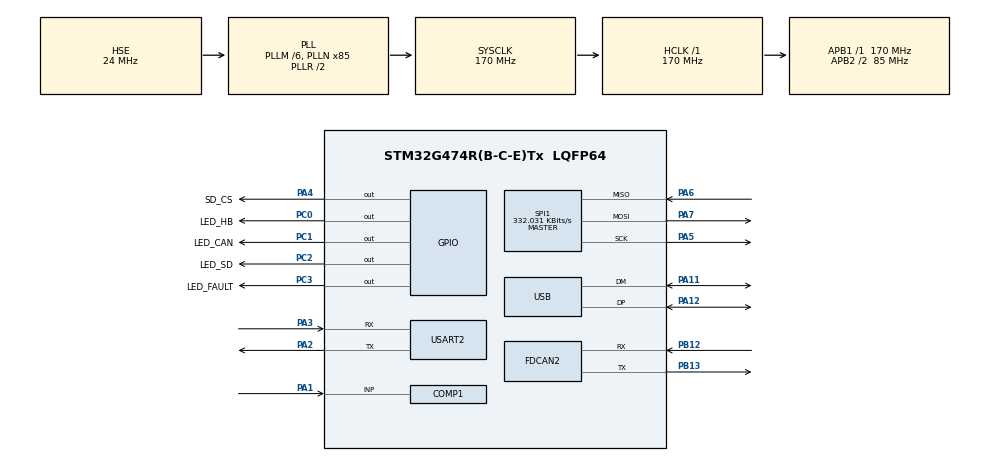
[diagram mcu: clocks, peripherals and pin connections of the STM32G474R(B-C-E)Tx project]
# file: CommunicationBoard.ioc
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COMP1.Hysteresis=COMP_HYSTERESIS_20MV
COMP1.TriggerMode=COMP_TRIGGERMODE_IT_FALLING
Dma.Request0=SPI1_RX
Dma.Request1=SPI1_TX
Dma.Request2=USART2_TX
Dma.SPI1_RX.0.Direction=DMA_PERIPH_TO_MEMORY
Dma.SPI1_RX.0.EventEnable=DISABLE
Dma.SPI1_RX.0.Instance=DMA1_Channel1
Dma.SPI1_RX.0.MemDataAlignment=DMA_MDATAALIGN_BYTE
Dma.SPI1_RX.0.MemInc=DMA_MINC_ENABLE
Dma.SPI1_RX.0.Mode=DMA_NORMAL
Dma.SPI1_RX.0.PeriphDataAlignment=DMA_PDATAALIGN_BYTE
Dma.SPI1_RX.0.PeriphInc=DMA_PINC_DISABLE
Dma.SPI1_RX.0.Polarity=HAL_DMAMUX_REQ_GEN_RISING
Dma.SPI1_RX.0.Priority=DMA_PRIORITY_LOW
Dma.SPI1_RX.0.RequestNumber=1
Dma.SPI1_RX.0.SignalID=NONE
Dma.SPI1_RX.0.SyncEnable=DISABLE
Dma.SPI1_RX.0.SyncPolarity=HAL_DMAMUX_SYNC_NO_EVENT
Dma.SPI1_RX.0.SyncRequestNumber=1
Dma.SPI1_RX.0.SyncSignalID=NONE
Dma.SPI1_TX.1.Direction=DMA_MEMORY_TO_PERIPH
Dma.SPI1_TX.1.EventEnable=DISABLE
Dma.SPI1_TX.1.Instance=DMA1_Channel2
Dma.SPI1_TX.1.MemDataAlignment=DMA_MDATAALIGN_BYTE
Dma.SPI1_TX.1.MemInc=DMA_MINC_ENABLE
Dma.SPI1_TX.1.Mode=DMA_NORMAL
Dma.SPI1_TX.1.PeriphDataAlignment=DMA_PDATAALIGN_BYTE
Dma.SPI1_TX.1.PeriphInc=DMA_PINC_DISABLE
Dma.SPI1_TX.1.Polarity=HAL_DMAMUX_REQ_GEN_RISING
Dma.SPI1_TX.1.Priority=DMA_PRIORITY_LOW
Dma.SPI1_TX.1.RequestNumber=1
Dma.SPI1_TX.1.SignalID=NONE
Dma.SPI1_TX.1.SyncEnable=DISABLE
Dma.SPI1_TX.1.SyncPolarity=HAL_DMAMUX_SYNC_NO_EVENT
Dma.SPI1_TX.1.SyncRequestNumber=1
Dma.SPI1_TX.1.SyncSignalID=NONE
Dma.USART2_TX.2.Direction=DMA_MEMORY_TO_PERIPH
Dma.USART2_TX.2.EventEnable=DISABLE
Dma.USART2_TX.2.Instance=DMA1_Channel3
Dma.USART2_TX.2.MemDataAlignment=DMA_MDATAALIGN_BYTE
Dma.USART2_TX.2.MemInc=DMA_MINC_ENABLE
Dma.USART2_TX.2.Mode=DMA_NORMAL
Dma.USART2_TX.2.PeriphDataAlignment=DMA_PDATAALIGN_BYTE
Dma.USART2_TX.2.PeriphInc=DMA_PINC_DISABLE
Dma.USART2_TX.2.Polarity=HAL_DMAMUX_REQ_GEN_RISING
Dma.USART2_TX.2.Priority=DMA_PRIORITY_LOW
Dma.USART2_TX.2.RequestNumber=1
Dma.USART2_TX.2.SignalID=NONE
Dma.USART2_TX.2.SyncEnable=DISABLE
Dma.USART2_TX.2.SyncPolarity=HAL_DMAMUX_SYNC_NO_EVENT
Dma.USART2_TX.2.SyncRequestNumber=1
Dma.USART2_TX.2.SyncSignalID=NONE
FATFS._FS_REENTRANT=0
FATFS._USE_EXPAND=1
FATFS._USE_LFN=1
FDCAN2.AutoRetransmission=ENABLE
FDCAN2.CalculateBaudRateNominal=999999
FDCAN2.CalculateTimeBitNominal=1000
FDCAN2.CalculateTimeQuantumNominal=58.82352941176471
FDCAN2.NominalPrescaler=10
FDCAN2.NominalSyncJumpWidth=2
FDCAN2.NominalTimeSeg1=14
FDCAN2.NominalTimeSeg2=2
FDCAN2.StdFiltersNbr=1
IWDG.Prescaler=IWDG_PRESCALER_32
IWDG.Reload=1999
Mcu.Family=STM32G4
Mcu.Name=STM32G474R(B-C-E)Tx
Mcu.Package=LQFP64
NVIC.COMP1_2_3_IRQn=true\:5\:0\:false\:false\:true\:false\:true\:true
NVIC.DMA1_Channel1_IRQn=true\:7\:0\:false\:false\:true\:false\:true\:true
NVIC.DMA1_Channel2_IRQn=true\:7\:0\:false\:false\:true\:false\:true\:true
NVIC.DMA1_Channel3_IRQn=true\:10\:0\:false\:false\:true\:false\:true\:true
NVIC.FDCAN2_IT0_IRQn=true\:6\:0\:false\:false\:true\:false\:true\:true
NVIC.PriorityGroup=NVIC_PRIORITYGROUP_4
NVIC.TIM2_IRQn=true\:9\:0\:false\:false\:true\:false\:true\:true
NVIC.USART2_IRQn=true\:10\:0\:false\:false\:true\:false\:true\:true
PA1.Mode=INP
PA1.Signal=COMP1_INP
PA11.Mode=Device
PA11.Signal=USB_DM
PA12.Mode=Device
PA12.Signal=USB_DP
PA13.Mode=Serial_Wire
PA13.Signal=SYS_JTMS-SWDIO
PA14.Mode=Serial_Wire
PA14.Signal=SYS_JTCK-SWCLK
PA2.Mode=Asynchronous
PA2.Signal=USART2_TX
PA3.Mode=Asynchronous
PA3.Signal=USART2_RX
PA4.GPIO_Label=SD_CS
PA4.PinState=GPIO_PIN_SET
PA4.Signal=GPIO_Output
PA5.GPIO_Speed=GPIO_SPEED_FREQ_VERY_HIGH
PA5.Mode=Full_Duplex_Master
PA5.Signal=SPI1_SCK
PA6.GPIO_PuPd=GPIO_PULLUP
PA6.GPIO_Speed=GPIO_SPEED_FREQ_VERY_HIGH
PA6.Mode=Full_Duplex_Master
PA6.Signal=SPI1_MISO
PA7.GPIO_Speed=GPIO_SPEED_FREQ_VERY_HIGH
PA7.Mode=Full_Duplex_Master
PA7.Signal=SPI1_MOSI
PB12.Mode=FDCAN_Activate
PB12.Signal=FDCAN2_RX
PB13.Mode=FDCAN_Activate
PB13.Signal=FDCAN2_TX
PC0.GPIO_Label=LED_HB
PC0.Signal=GPIO_Output
PC1.GPIO_Label=LED_CAN
PC1.Signal=GPIO_Output
PC14-OSC32_IN.Mode=LSE-External-Oscillator
PC14-OSC32_IN.Signal=RCC_OSC32_IN
PC15-OSC32_OUT.Mode=LSE-External-Oscillator
PC15-OSC32_OUT.Signal=RCC_OSC32_OUT
PC2.GPIO_Label=LED_SD
PC2.Signal=GPIO_Output
PC3.GPIO_Label=LED_FAULT
PC3.Signal=GPIO_Output
PF0-OSC_IN.Mode=HSE-External-Oscillator
PF0-OSC_IN.Signal=RCC_OSC_IN
PF1-OSC_OUT.Mode=HSE-External-Oscillator
PF1-OSC_OUT.Signal=RCC_OSC_OUT
ProjectManager.HeapSize=0x1000
ProjectManager.StackSize=0x2000
ProjectManager.TargetToolchain=STM32CubeIDE
RCC.ADC12Freq_Value=170000000
RCC.ADC345Freq_Value=170000000
RCC.AHBFreq_Value=170000000
RCC.APB1Freq_Value=170000000
RCC.APB1TimFreq_Value=170000000
RCC.APB2CLKDivider=RCC_HCLK_DIV2
RCC.APB2Freq_Value=85000000
RCC.APB2TimFreq_Value=170000000
RCC.CK48CLockSelection=RCC_USBCLKSOURCE_HSI48
RCC.CortexFreq_Value=170000000
RCC.EXTERNAL_CLOCK_VALUE=12288000
RCC.HCLKFreq_Value=170000000
RCC.HSE_VALUE=24000000
RCC.HSI48_VALUE=48000000
RCC.HSI_VALUE=16000000
RCC.PLLM=RCC_PLLM_DIV6
RCC.PLLN=85
RCC.PLLQ=RCC_PLLQ_DIV4
RCC.PLLSourceVirtual=RCC_PLLSOURCE_HSE
RCC.RTCClockSelection=RCC_RTCCLKSOURCE_LSE
RCC.SYSCLKFreq_VALUE=170000000
RCC.SYSCLKSource=RCC_SYSCLKSOURCE_PLLCLK
RCC.USBFreq_Value=48000000
RCC.VCOOutputFreq_Value=340000000
SPI1.BaudRatePrescaler=SPI_BAUDRATEPRESCALER_256
SPI1.CalculateBaudRate=332.031 KBits/s
SPI1.DataSize=SPI_DATASIZE_8BIT
SPI1.Direction=SPI_DIRECTION_2LINES
SPI1.Mode=SPI_MODE_MASTER
SPI1.VirtualType=VM_MASTER
TIM2.Period=4294967295
TIM2.Prescaler=169
USART2.VirtualMode-Asynchronous=VM_ASYNC
VP_COMP1_VS_VREFINT.Mode=VREFINT
VP_FATFS_VS_Generic.Mode=User_defined
VP_IWDG_VS_IWDG.Mode=IWDG_Activate
VP_RTC_VS_RTC_Activate.Mode=RTC_Enabled
VP_RTC_VS_RTC_Calendar.Mode=RTC_Calendar
VP_SYS_VS_DBSignals.Mode=DisableDeadBatterySignals
VP_TIM2_VS_ClockSourceINT.Mode=Internal
board=custom

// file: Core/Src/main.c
/* USER CODE BEGIN Header */
/**
  ******************************************************************************
  * @file           : main.c
  * @brief          : Main program body
  ******************************************************************************
  * @attention
  *
  * Copyright (c) 2026 STMicroelectronics.
  * All rights reserved.
  *
  * This software is licensed under terms that can be found in the LICENSE file
  * in the root directory of this software component.
  * If no LICENSE file comes with this software, it is provided AS-IS.
  *
  ******************************************************************************
  */
/* USER CODE END Header */
#include "main.h"
#include "comp.h"
#include "dma.h"
#include "app_fatfs.h"
#include "fdcan.h"
#include "iwdg.h"
#include "rtc.h"
#include "spi.h"
#include "tim.h"
#include "usart.h"
#include "usb.h"
#include "gpio.h"

/* USER CODE BEGIN Includes */
#include "app_main.h"
/* USER CODE END Includes */

void SystemClock_Config(void);

int main(void)
{

  /* MCU Configuration--------------------------------------------------------*/

  /* Reset of all peripherals, Initializes the Flash interface and the Systick. */
  HAL_Init();

  /* Configure the system clock */
  SystemClock_Config();

  /* Initialize all configured peripherals */
  MX_GPIO_Init();
  MX_DMA_Init();
  MX_COMP1_Init();
  MX_FDCAN2_Init();
  MX_RTC_Init();
  MX_SPI1_Init();
  MX_USB_PCD_Init();
  if (MX_FATFS_Init() != APP_OK) {
    Error_Handler();
  }
  MX_TIM2_Init();
  MX_USART2_UART_Init();
  MX_IWDG_Init();
  /* USER CODE BEGIN 2 */
  app_main();
  /* USER CODE END 2 */

  /* Infinite loop */
  while (1)
  {

    /* USER CODE BEGIN 3 */
    app_loop();
  }
  /* USER CODE END 3 */
}

void SystemClock_Config(void)
{
  RCC_OscInitTypeDef RCC_OscInitStruct = {0};
  RCC_ClkInitTypeDef RCC_ClkInitStruct = {0};

  /** Configure the main internal regulator output voltage
  */
  HAL_PWREx_ControlVoltageScaling(PWR_REGULATOR_VOLTAGE_SCALE1_BOOST);

  /** Configure LSE Drive Capability
  */
  HAL_PWR_EnableBkUpAccess();
  __HAL_RCC_LSEDRIVE_CONFIG(RCC_LSEDRIVE_LOW);

  /** Initializes the RCC Oscillators according to the specified parameters
  * in the RCC_OscInitTypeDef structure.
  */
  RCC_OscInitStruct.OscillatorType = RCC_OSCILLATORTYPE_HSI48|RCC_OSCILLATORTYPE_LSI
                              |RCC_OSCILLATORTYPE_HSE|RCC_OSCILLATORTYPE_LSE;
  RCC_OscInitStruct.HSEState = RCC_HSE_ON;
  RCC_OscInitStruct.LSEState = RCC_LSE_ON;
  RCC_OscInitStruct.LSIState = RCC_LSI_ON;
  RCC_OscInitStruct.HSI48State = RCC_HSI48_ON;
  RCC_OscInitStruct.PLL.PLLState = RCC_PLL_ON;
  RCC_OscInitStruct.PLL.PLLSource = RCC_PLLSOURCE_HSE;
  RCC_OscInitStruct.PLL.PLLM = RCC_PLLM_DIV6;
  RCC_OscInitStruct.PLL.PLLN = 85;
  RCC_OscInitStruct.PLL.PLLP = RCC_PLLP_DIV2;
  RCC_OscInitStruct.PLL.PLLQ = RCC_PLLQ_DIV4;
  RCC_OscInitStruct.PLL.PLLR = RCC_PLLR_DIV2;
  if (HAL_RCC_OscConfig(&RCC_OscInitStruct) != HAL_OK)
  {
    Error_Handler();
  }

  /** Initializes the CPU, AHB and APB buses clocks
  */
  RCC_ClkInitStruct.ClockType = RCC_CLOCKTYPE_HCLK|RCC_CLOCKTYPE_SYSCLK
                              |RCC_CLOCKTYPE_PCLK1|RCC_CLOCKTYPE_PCLK2;
  RCC_ClkInitStruct.SYSCLKSource = RCC_SYSCLKSOURCE_PLLCLK;
  RCC_ClkInitStruct.AHBCLKDivider = RCC_SYSCLK_DIV1;
  RCC_ClkInitStruct.APB1CLKDivider = RCC_HCLK_DIV1;
  RCC_ClkInitStruct.APB2CLKDivider = RCC_HCLK_DIV2;

  if (HAL_RCC_ClockConfig(&RCC_ClkInitStruct, FLASH_LATENCY_4) != HAL_OK)
  {
    Error_Handler();
  }
}

void Error_Handler(void)
{
  /* USER CODE BEGIN Error_Handler_Debug */
  /* Reset rather than spin. Error_Handler() can run before the watchdog is started (a
   * crystal that will not start makes SystemClock_Config() fail), and a spin there
   * would hang the board for good with no LED and no reset. */
  __disable_irq();
  NVIC_SystemReset();
  /* USER CODE END Error_Handler_Debug */
}
